# ESP32-P4 register map
Vendor: ESPRESSIF SYSTEMS (SHANGHAI) CO., LTD.; Series: ESP32 P-Series; File version: 2
CPU: RV32IMAFC r0p0, little endian, no MPU, FPU, 0 interrupt priority bits
Address unit: 32 bits
Registers are 32-bit, read-write, reset 0x0 unless marked. A register's access mark holds for its fields unless they carry their own. Offsets are from the block's base; [hi:lo] are bit positions; {n}, {i} and the like mark numbered series.

## AXI_ICM — AXI_ICM Peripheral
Base 0x500A4000
0x00 VERID_FILEDS ro reset 0x3430342A
  [31:0] ICM_REG_VERID
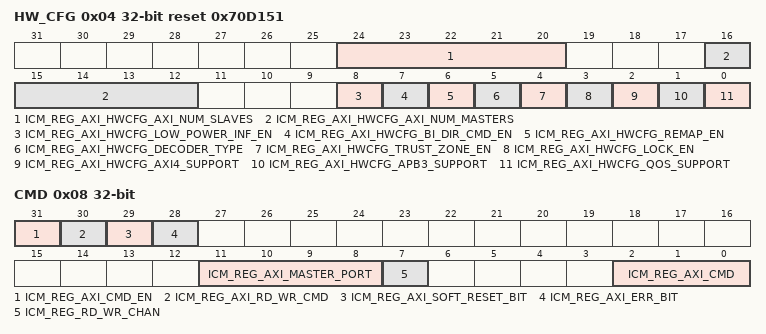
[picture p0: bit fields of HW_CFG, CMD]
0x04 HW_CFG ro reset 0x70D151
  [24:20] ICM_REG_AXI_HWCFG_AXI_NUM_SLAVES, [16:12] ICM_REG_AXI_HWCFG_AXI_NUM_MASTERS, [8] ICM_REG_AXI_HWCFG_LOW_POWER_INF_EN, [7] ICM_REG_AXI_HWCFG_BI_DIR_CMD_EN, [6] ICM_REG_AXI_HWCFG_REMAP_EN, [5] ICM_REG_AXI_HWCFG_DECODER_TYPE, [4] ICM_REG_AXI_HWCFG_TRUST_ZONE_EN, [3] ICM_REG_AXI_HWCFG_LOCK_EN, [2] ICM_REG_AXI_HWCFG_AXI4_SUPPORT, [1] ICM_REG_AXI_HWCFG_APB3_SUPPORT, [0] ICM_REG_AXI_HWCFG_QOS_SUPPORT
0x08 CMD access per field
  [31] ICM_REG_AXI_CMD_EN rw, [30] ICM_REG_AXI_RD_WR_CMD rw, [29] ICM_REG_AXI_SOFT_RESET_BIT rw, [28] ICM_REG_AXI_ERR_BIT ro, [11:8] ICM_REG_AXI_MASTER_PORT rw, [7] ICM_REG_RD_WR_CHAN rw, [2:0] ICM_REG_AXI_CMD rw
0x0C DATA
  [31:0] ICM_REG_DATA

## IO_MUX — Input/Output Multiplexer
Base 0x500E1000
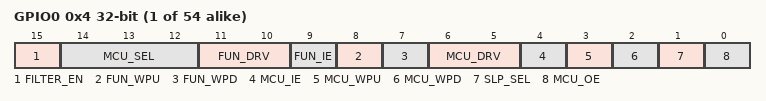
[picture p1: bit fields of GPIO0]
{0x4+4i} GPIO{i} (i=0..53) — IO_MUX Control Register
  [15] FILTER_EN — Configures whether or not to enable filter for pin input signals. 0: Disable 1: Enable
  [14:12] MCU_SEL — Configures to select IO MUX function for this pin. 0: Select Function 0 1: Select Function 1 ......
  [11:10] FUN_DRV — Configures the drive strength of GPIOn. 0: ~5 mA 1: ~10 mA 2: ~20 mA 3: ~40 mA
  [9] FUN_IE — Configures whether or not to enable input of GPIOn. 0: Disable 1: Enable
  [8] FUN_WPU — Configures whether or not enable pull-up resistor of GPIOn. 0: Disable 1: Enable
  [7] FUN_WPD — Configures whether or not to enable pull-down resistor of GPIOn. 0: Disable 1: Enable
  [6:5] MCU_DRV — Configures the drive strength of GPIOn during sleep mode. 0: ~5 mA 1: ~10 mA 2: ~20 mA 3: ~40 mA
  [4] MCU_IE — Configures whether or not to enable the input of GPIOn during sleep mode. 0: Disable 1: Enable
  [3] MCU_WPU — Configures whether or not to enable pull-up resistor of GPIOn during sleep mode. 0: Disable 1: Enable
  [2] MCU_WPD — Configure whether or not to enable pull-down resistor of GPIOn during sleep mode. 0: Disable 1: Enable
  [1] SLP_SEL — Configures whether or not to enter sleep mode for GPIOn. 0: Not enter 1: Enter
  [0] MCU_OE — Configures whether or not to enable the output of GPIOn in sleep mode. 0: Disable 1: Enable
0x104 DATE reset 0x201222 — iomux version
  [27:0] DATE — csv date

## LP_INTR — Low-power Interrupt Controller
Base 0x5012C000
0x00 SW_INT_RAW — need_des
  [31] LP_SW_INT_RAW
0x04 SW_INT_ST ro — need_des
  [31] LP_SW_INT_ST
0x08 SW_INT_ENA — need_des
  [31] LP_SW_INT_ENA
0x0C SW_INT_CLR wo — need_des
  [31] LP_SW_INT_CLR
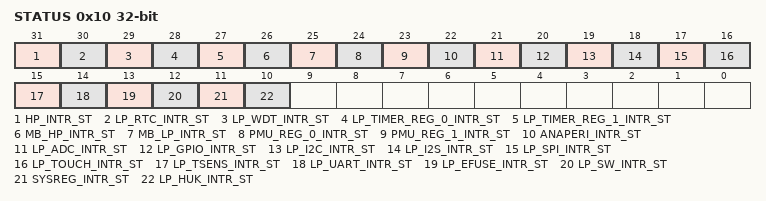
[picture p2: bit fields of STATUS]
0x10 STATUS ro — need_des
  [31] HP_INTR_ST — need_des
  [30] LP_RTC_INTR_ST — need_des
  [29] LP_WDT_INTR_ST — need_des
  [28] LP_TIMER_REG_0_INTR_ST — need_des
  [27] LP_TIMER_REG_1_INTR_ST — need_des
  [26] MB_HP_INTR_ST — need_des
  [25] MB_LP_INTR_ST — need_des
  [24] PMU_REG_0_INTR_ST — need_des
  [23] PMU_REG_1_INTR_ST — need_des
  [22] ANAPERI_INTR_ST — need_des
  [21] LP_ADC_INTR_ST — need_des
  [20] LP_GPIO_INTR_ST — need_des
  [19] LP_I2C_INTR_ST — need_des
  [18] LP_I2S_INTR_ST — need_des
  [17] LP_SPI_INTR_ST — need_des
  [16] LP_TOUCH_INTR_ST — need_des
  [15] LP_TSENS_INTR_ST — need_des
  [14] LP_UART_INTR_ST — need_des
  [13] LP_EFUSE_INTR_ST — need_des
  [12] LP_SW_INTR_ST — need_des
  [11] SYSREG_INTR_ST — need_des
  [10] LP_HUK_INTR_ST — need_des
0x3FC DATE — need_des
  [31] CLK_EN

## LP_PERI — LP_PERI Peripheral
Base 0x50120000
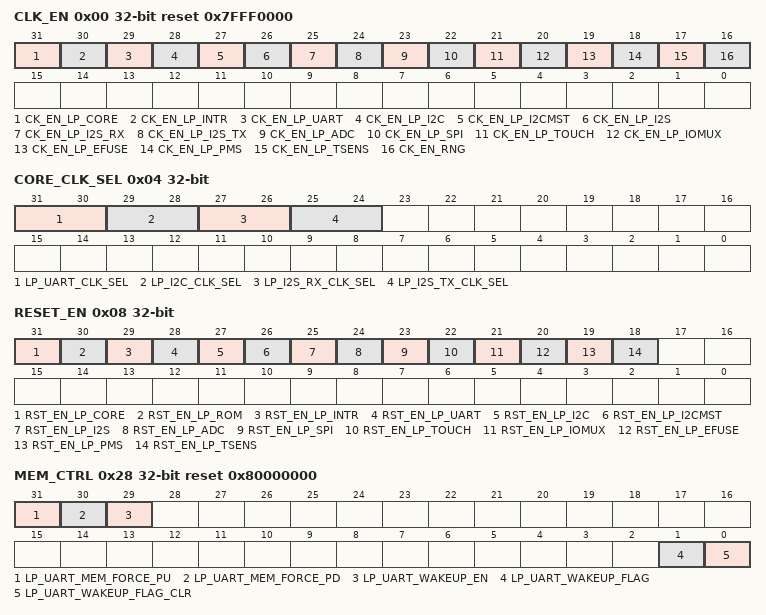
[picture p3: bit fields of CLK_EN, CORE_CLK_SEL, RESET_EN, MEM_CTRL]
0x00 CLK_EN reset 0x7FFF0000 — need_des
  [31] CK_EN_LP_CORE — write 1 to force on lp_core clk
  [30] CK_EN_LP_INTR — need_des
  [29] CK_EN_LP_UART — need_des
  [28] CK_EN_LP_I2C — need_des
  [27] CK_EN_LP_I2CMST — need_des
  [26] CK_EN_LP_I2S — need_des
  [25] CK_EN_LP_I2S_RX — need_des
  [24] CK_EN_LP_I2S_TX — need_des
  [23] CK_EN_LP_ADC — need_des
  [22] CK_EN_LP_SPI — need_des
  [21] CK_EN_LP_TOUCH — need_des
  [20] CK_EN_LP_IOMUX — need_des
  [19] CK_EN_LP_EFUSE — need_des
  [18] CK_EN_LP_PMS — need_des
  [17] CK_EN_LP_TSENS — need_des
  [16] CK_EN_RNG — need_des
0x04 CORE_CLK_SEL — need_des
  [31:30] LP_UART_CLK_SEL — need_des
  [29:28] LP_I2C_CLK_SEL — need_des
  [27:26] LP_I2S_RX_CLK_SEL — need_des
  [25:24] LP_I2S_TX_CLK_SEL — need_des
0x08 RESET_EN access per field — need_des
  [31] RST_EN_LP_CORE wo — need_des
  [30] RST_EN_LP_ROM rw — need_des
  [29] RST_EN_LP_INTR rw — need_des
  [28] RST_EN_LP_UART rw — need_des
  [27] RST_EN_LP_I2C rw — need_des
  [26] RST_EN_LP_I2CMST rw — need_des
  [25] RST_EN_LP_I2S rw — need_des
  [24] RST_EN_LP_ADC rw — need_des
  [23] RST_EN_LP_SPI rw — need_des
  [22] RST_EN_LP_TOUCH rw — need_des
  [21] RST_EN_LP_IOMUX rw — need_des
  [20] RST_EN_LP_EFUSE rw — need_des
  [19] RST_EN_LP_PMS rw — need_des
  [18] RST_EN_LP_TSENS rw — need_des
0x0C CPU reset 0x80000000 — need_des
  [31] LPCORE_DBGM_UNAVAILABLE
0x28 MEM_CTRL access per field reset 0x80000000 — need_des
  [31] LP_UART_MEM_FORCE_PU rw — need_des
  [30] LP_UART_MEM_FORCE_PD rw — need_des
  [29] LP_UART_WAKEUP_EN rw — need_des
  [1] LP_UART_WAKEUP_FLAG rw — need_des
  [0] LP_UART_WAKEUP_FLAG_CLR wo — need_des
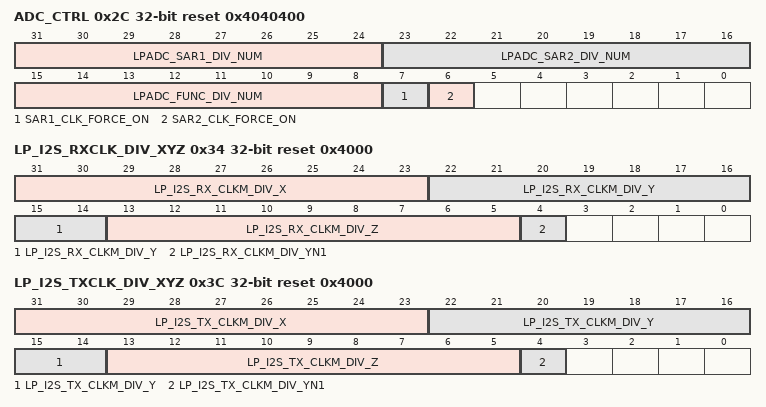
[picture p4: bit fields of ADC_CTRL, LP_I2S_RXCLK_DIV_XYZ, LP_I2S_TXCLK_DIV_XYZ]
0x2C ADC_CTRL reset 0x4040400 — need_des
  [31:24] LPADC_SAR1_DIV_NUM — need_des
  [23:16] LPADC_SAR2_DIV_NUM — need_des
  [15:8] LPADC_FUNC_DIV_NUM — need_des
  [7] SAR1_CLK_FORCE_ON — need_des
  [6] SAR2_CLK_FORCE_ON — need_des
0x30 LP_I2S_RXCLK_DIV_NUM reset 0x2000000 — need_des
  [31:24] LP_I2S_RX_CLKM_DIV_NUM
0x34 LP_I2S_RXCLK_DIV_XYZ reset 0x4000 — need_des
  [31:23] LP_I2S_RX_CLKM_DIV_X — need_des
  [22:14] LP_I2S_RX_CLKM_DIV_Y — need_des
  [13:5] LP_I2S_RX_CLKM_DIV_Z — need_des
  [4] LP_I2S_RX_CLKM_DIV_YN1 — need_des
0x38 LP_I2S_TXCLK_DIV_NUM reset 0x2000000 — need_des
  [31:24] LP_I2S_TX_CLKM_DIV_NUM
0x3C LP_I2S_TXCLK_DIV_XYZ reset 0x4000 — need_des
  [31:23] LP_I2S_TX_CLKM_DIV_X — need_des
  [22:14] LP_I2S_TX_CLKM_DIV_Y — need_des
  [13:5] LP_I2S_TX_CLKM_DIV_Z — need_des
  [4] LP_I2S_TX_CLKM_DIV_YN1 — need_des
0x3FC DATE — need_des
  [31] CLK_EN
